VERSION "Mon"

NS_ :

BS_:

BU_: Mon ADAS Camera Gateway EPS APA Radar ESC radar
VAL_TABLE_ VitSig_LKA_main_switch 1 "LKA ON" 0 "LKA OFF" ;
VAL_TABLE_ VitSig_LC_Mode 3 "车道居中控制" 2 "车道保持辅助" 1 "车道偏离预警" 0 "预留" ;
VAL_TABLE_ VitSig_State_of_EPS_for_LKA 7 "Reserved" 6 "Reserved" 5 "Reserved" 4 "defect" 3 "active" 2 "available" 1 "authorized" 0 "unauthorized" ;
VAL_TABLE_ VitSig_Steering_wheel_sensor_dir 1 "Negative angles, decrease" 0 "Positive angles, increase" ;
VAL_TABLE_ VitSig_BCM_Status_Indicator 3 "Left and right indicator active" 2 "Left Indicator active" 1 "Right Indicator active" 0 "Indicator inactive" ;
VAL_TABLE_ VitSig_TCU_Gear_lever_position 15 "CMF disabled or unavailable" 14 "Reserved" 13 "Reserved" 12 "Reserved" 11 "Manual mode / Reserved1100" 10 "Reserved" 9 "Reserved" 8 "Reserved" 7 "Reserved" 6 "Reserved" 5 "Reserved" 4 "Reserved" 3 "D" 2 "N" 1 "R" 0 "P" ;
VAL_TABLE_ VLlaneType_valueTable 6 "road edge" 5 "bott's dotts" 4 "double lane mark" 3 "solid" 2 "dashed" 1 "undecided" 0 "invalid" ;
VAL_TABLE_ VLquality_valueTable 1 "high" 0 "low" ;
VAL_TABLE_ VitSig_General_state_of_LKA_3F2 7 "Reserved" 6 "Collision risk" 5 "Defect" 4 "Active" 3 "Autorized" 2 "Selected" 1 "Unselected" 0 "Unavailable" ;
VAL_TABLE_ VitSig_Deadman_dedicated_button 3 "Fault" 2 "Unconfigured" 1 "Request" 0 "No request" ;
VAL_TABLE_ VitSig_ASR_connection_dis_demand 1 "ASR disconnection requested" 0 "No ASR disconnection requested" ;
VAL_TABLE_ VitSig_Trailer_Present 1 "Trailer presence" 0 "Trailer absence" ;
VAL_TABLE_ VitSig_Permit_to_know_if_LKALPA 1 "LPA function" 0 "LKA function" ;
VAL_TABLE_ VitSig_TSR_Vision_Only_Sign_Type 255 "预留" 16 "预留" 15 "禁止驶入标志" 14 "停车让行标志" 13 "注意儿童标志" 12 "注意行人标志" 11 "注意危险标志" 10 "注意横风标志" 9 "注意信号灯标志" 8 "注意落石标志" 7 "易滑标志" 6 "下陡坡标志" 5 "上陡坡标志" 4 "十字交叉标志" 3 "施工标志" 2 "禁止右转标志" 1 "禁止左转标志" 0 "No TSR detected" ;
VAL_TABLE_ VitSig_ISA_Status 2 "ISA sign flash(over speed)" 1 "ISA system ON with limit value" 0 "ISA system OFF" ;
VAL_TABLE_ VitSig_ISA_Sign_Type 3 "End of speed limit sign" 2 "Speed limit sign with value" 1 "Speed limit sign without value" 0 "Default value" ;
VAL_TABLE_ VitSig_ISA_Value 31 "reserved" 30 "reserved" 29 "145km/h speed limit sign" 28 "135km/h speed limit sign" 27 "125km/h speed limit sign" 26 "115km/h speed limit sign" 25 "105km/h speed limit sign" 24 "95km/h speed limit sign" 23 "85km/h speed limit sign" 22 "75km/h speed limit sign" 21 "65km/h speed limit sign" 20 "55km/h speed limit sign" 19 "45km/h speed limit sign" 18 "35km/h speed limit sign" 17 "25km/h speed limit sign" 16 "15km/h speed limit sign" 15 "5km/h speed limit sign" 14 "140km/h speed limit sign" 13 "130km/h speed limit sign" 12 "120km/h speed limit sign" 11 "110km/h speed limit sign" 10 "100km/h speed limit sign" 9 "90km/h speed limit sign" 8 "80km/h speed limit sign" 7 "70km/h speed limit sign" 6 "60km/h speed limit sign" 5 "50km/h speed limit sign" 4 "40km/h speed limit sign" 3 "30km/h speed limit sign" 2 "20km/h speed limit sign" 1 "10km/h speed limit sign" 0 "No speed limit sign detected" ;
VAL_TABLE_ VitSig_ISA_Popup_text 3 "System fault" 2 "ISA system OFF (From ON to OFF)" 1 "ISA system ON (From OFF to ON)" 0 "No popup" ;
VAL_TABLE_ VitSig_ECU_operating_phase 15 "reserved" 14 "reserved" 13 "reserved" 12 "reserved" 11 "reserved" 10 "Service Alignment in processing" 9 "System fully operational" 8 "reserved" 7 "Camera Degraded" 6 "reserved" 5 "Camera Blocked/No image" 4 "reserved" 3 "Camera not calibrated" 2 "System Initializing/Warming Up" 1 "Status not available" 0 "system error" ;
VAL_TABLE_ VitSig_LKA_Switch_State 1 "LKA Switch ON" 0 "LKA Switch OFF" ;
VAL_TABLE_ VitSig_LKA_Mode_from_Camera 3 "LCA+LDW (resolved)" 2 "LKA+LDW" 1 "LDW only" 0 "OFF" ;
VAL_TABLE_ VitSig_hands_off_warning 1 "Hands off warning" 0 "No Hands off warning" ;
VAL_TABLE_ VitSig_LDW_Flag 3 "Invalid" 2 "Right LDW warining" 1 "Left LDW warining" 0 "No LDW warning" ;
VAL_TABLE_ VitSig_Vehicle_Lane_Display 15 "Invalid" 14 "Reserved" 13 "Reserved" 12 "Reserved" 11 "Reserved" 10 "Reserved" 9 "LKA intervention or LDW warning " 8 "LKA intervention or LDW warning " 7 "LKA intervention or LDW warning " 6 "LKA intervention or LDW warning " 5 "both lanes detected,both green" 4 "only right lane detected, green" 3 "only left detected,left green" 2 "available but no lane detected" 1 "ON but not in the working range " 0 "OFF and no lane line displayed" ;
VAL_TABLE_ VitSig_LKA_Status_Display 3 "Invalid" 2 "ON and system fault detected,red" 1 "ON and no system fault,  green" 0 "LKA + LDW OFF, no icon display" ;
VAL_TABLE_ VitSig_LDW_Status_Display 3 "Invalid" 2 "ON and system fault detected,red" 1 "ON and no system fault,green" 0 "LDW Only OFF, no icon display" ;
VAL_TABLE_ VitSig_LKA_action_indication 7 "Invalid" 6 "Reserved" 5 "Reserved" 4 "Reserved" 3 "available and with LKA,orange" 2 "available and without LKA, green" 1 "ON but not in working range" 0 "LKA+LDW OFF,no icon display" ;

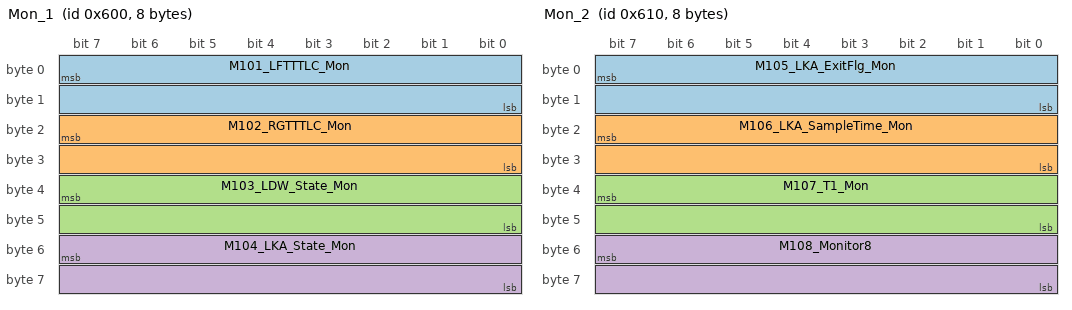
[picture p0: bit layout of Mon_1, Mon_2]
BO_ 1536 Mon_1: 8 Mon
 SG_ M101_LFTTTLC_Mon : 7|16@0- (0.01,0) [-327.68|327.67] "Mon" Vector__XXX
 SG_ M102_RGTTTLC_Mon : 23|16@0- (0.01,0) [-327.68|327.67] "Mon" Vector__XXX
 SG_ M103_LDW_State_Mon : 39|16@0- (0.01,0) [-327.68|327.67] "Mon" Vector__XXX
 SG_ M104_LKA_State_Mon : 55|16@0- (0.01,0) [-327.68|327.67] "Mon" Vector__XXX

BO_ 1552 Mon_2: 8 Mon
 SG_ M105_LKA_ExitFlg_Mon : 7|16@0- (0.01,0) [-327.68|327.67] "Mon" Vector__XXX
 SG_ M106_LKA_SampleTime_Mon : 23|16@0- (0.01,0) [-327.68|327.67] "Mon" Vector__XXX
 SG_ M107_T1_Mon : 39|16@0- (0.01,0) [-327.68|327.67] "Mon" Vector__XXX
 SG_ M108_Monitor8 : 55|16@0- (0.01,0) [-327.68|327.67] "Mon" Vector__XXX

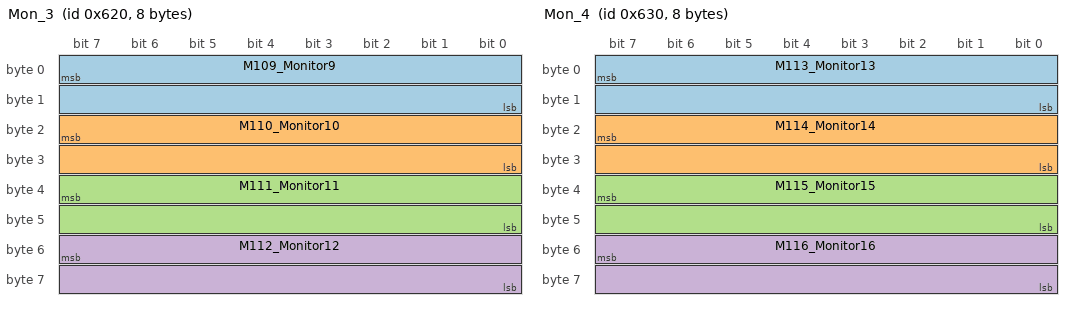
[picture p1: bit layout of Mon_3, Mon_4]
BO_ 1568 Mon_3: 8 Mon
 SG_ M109_Monitor9 : 7|16@0- (0.01,0) [-327.68|327.67] "Mon" Vector__XXX
 SG_ M110_Monitor10 : 23|16@0- (0.01,0) [-327.68|327.67] "Mon" Vector__XXX
 SG_ M111_Monitor11 : 39|16@0- (0.01,0) [-327.68|327.67] "Mon" Vector__XXX
 SG_ M112_Monitor12 : 55|16@0- (0.01,0) [-327.68|327.67] "Mon" Vector__XXX

BO_ 1584 Mon_4: 8 Mon
 SG_ M113_Monitor13 : 7|16@0- (0.01,0) [-327.68|327.67] "Mon" Vector__XXX
 SG_ M114_Monitor14 : 23|16@0- (0.01,0) [-327.68|327.67] "Mon" Vector__XXX
 SG_ M115_Monitor15 : 39|16@0- (0.01,0) [-327.68|327.67] "Mon" Vector__XXX
 SG_ M116_Monitor16 : 55|16@0- (0.01,0) [-327.68|327.67] "Mon" Vector__XXX

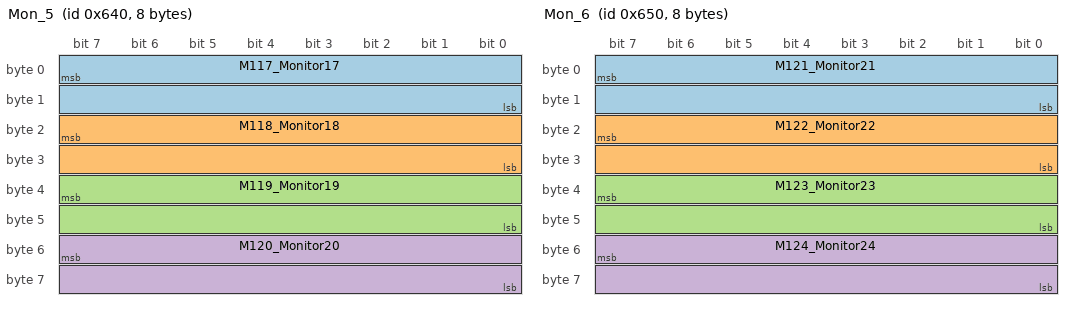
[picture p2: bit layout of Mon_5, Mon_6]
BO_ 1600 Mon_5: 8 Mon
 SG_ M117_Monitor17 : 7|16@0- (0.01,0) [-327.68|327.67] "Mon" Vector__XXX
 SG_ M118_Monitor18 : 23|16@0- (0.01,0) [-327.68|327.67] "Mon" Vector__XXX
 SG_ M119_Monitor19 : 39|16@0- (0.01,0) [-327.68|327.67] "Mon" Vector__XXX
 SG_ M120_Monitor20 : 55|16@0- (0.01,0) [-327.68|327.67] "Mon" Vector__XXX

BO_ 1616 Mon_6: 8 Mon
 SG_ M121_Monitor21 : 7|16@0- (0.01,0) [-327.68|327.67] "Mon" Vector__XXX
 SG_ M122_Monitor22 : 23|16@0- (0.01,0) [-327.68|327.67] "Mon" Vector__XXX
 SG_ M123_Monitor23 : 39|16@0- (0.01,0) [-327.68|327.67] "Mon" Vector__XXX
 SG_ M124_Monitor24 : 55|16@0- (0.01,0) [-327.68|327.67] "Mon" Vector__XXX

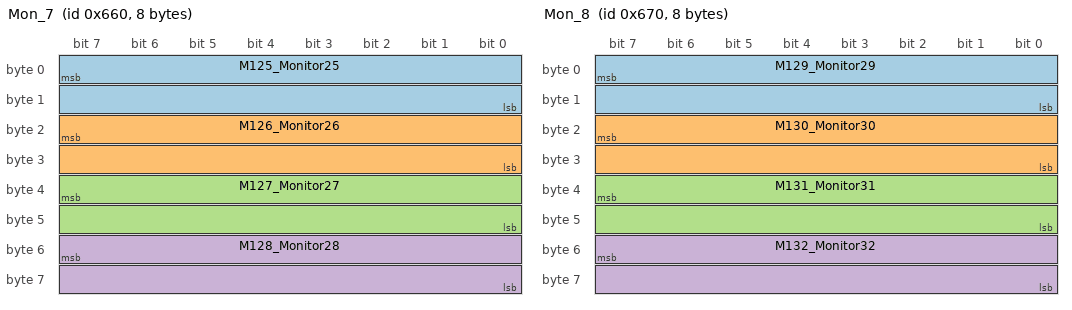
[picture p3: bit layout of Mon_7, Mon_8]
BO_ 1632 Mon_7: 8 Mon
 SG_ M125_Monitor25 : 7|16@0- (0.01,0) [-327.68|327.67] "Mon" Vector__XXX
 SG_ M126_Monitor26 : 23|16@0- (0.01,0) [-327.68|327.67] "Mon" Vector__XXX
 SG_ M127_Monitor27 : 39|16@0- (0.01,0) [-327.68|327.67] "Mon" Vector__XXX
 SG_ M128_Monitor28 : 55|16@0- (0.01,0) [-327.68|327.67] "Mon" Vector__XXX

BO_ 1648 Mon_8: 8 Mon
 SG_ M129_Monitor29 : 7|16@0- (0.01,0) [-327.68|327.67] "Mon" Vector__XXX
 SG_ M130_Monitor30 : 23|16@0- (0.01,0) [-327.68|327.67] "Mon" Vector__XXX
 SG_ M131_Monitor31 : 39|16@0- (0.01,0) [-327.68|327.67] "Mon" Vector__XXX
 SG_ M132_Monitor32 : 55|16@0- (0.01,0) [-327.68|327.67] "Mon" Vector__XXX

BO_ 1359 GW_550_PSA1: 8 Gateway
 SG_ LKA_main_switch : 5|1@0+ (1,0) [0|1] ""  ADAS,Camera
 SG_ LC_Mode : 7|2@0+ (1,0) [0|3] ""  ADAS,Camera

BO_ 1172 EPS_495_PSA1: 4 EPS
 SG_ State_of_EPS_for_LKA_function : 20|3@0+ (1,0) [0|7] ""  ADAS,Camera
 SG_ Steering_wheel_torque : 7|8@0- (0.25,0) [-32|31.5] "N.m"  ADAS,Camera

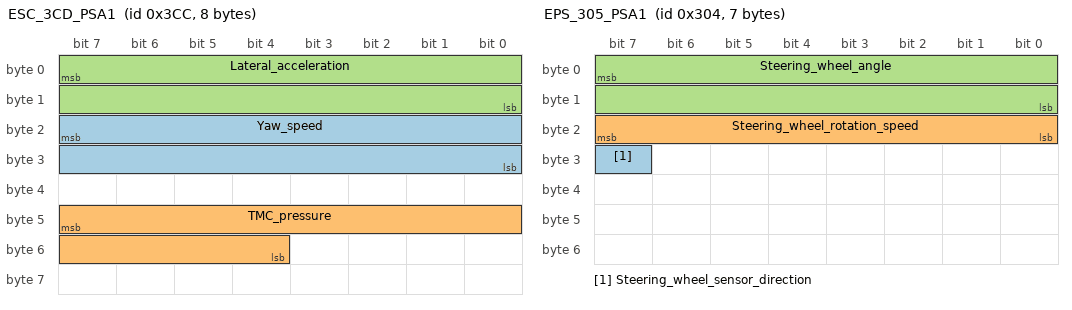
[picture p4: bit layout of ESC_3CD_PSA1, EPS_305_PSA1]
BO_ 972 ESC_3CD_PSA1: 8 ESC
 SG_ Yaw_speed : 23|16@0- (0.1,0) [-100|100] "Degree/s"  EPS,Gateway,APA,Camera,ADAS
 SG_ TMC_pressure : 47|12@0+ (0.1,-55) [-55|354.4] "Bar"  Gateway,APA,Radar,Camera,ADAS
 SG_ Lateral_acceleration : 7|16@0- (0.05,0) [-15|15] "m/s2"  EPS,Gateway,APA,Radar,Camera,ADAS

BO_ 908 ESC_38D_PSA1: 8 ESC
 SG_ Vehicle_speed_of_wheelsensor : 7|16@0+ (0.01,0) [0|655.34] "km/h"  EPS,Gateway,APA,Radar,Camera,ADAS

BO_ 812 GW_32D_PSA1: 8 Gateway
 SG_ ACCEL_LONGI_CALIB : 7|12@0+ (0.02,-40.96) [-40.96|40.92] "m/s2"  Radar,Camera,ADAS

BO_ 772 EPS_305_PSA1: 7 EPS
 SG_ Steering_wheel_sensor_direction : 31|1@0+ (1,0) [0|0] ""  ADAS,Camera,ESC,Gateway,Radar
 SG_ Steering_wheel_rotation_speed : 23|8@0+ (4,0) [0|1016] "Degree/s"  ADAS,APA,Camera,ESC,Gateway,Radar
 SG_ Steering_wheel_angle : 7|16@0- (0.1,0) [-780|780] "Degree"  ADAS,APA,Camera,ESC,Gateway,Radar

BO_ 1105 GW_452_PSA1: 6 Gateway
 SG_ BCM_Status_Indicator : 5|2@0+ (1,0) [0|0] ""  APA,Radar,Camera,ADAS

BO_ 840 GW_349_PSA1: 8 Gateway
 SG_ TCU_Gear_lever_position : 27|4@0+ (1,0) [0|0] ""  ESC,APA,Radar,Camera,ADAS

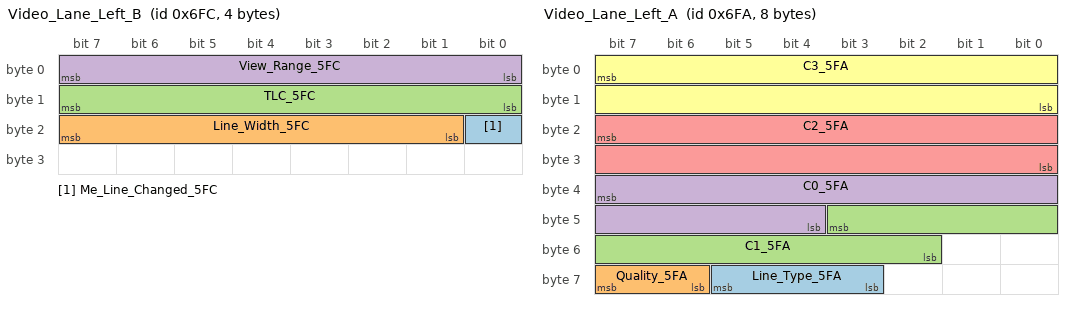
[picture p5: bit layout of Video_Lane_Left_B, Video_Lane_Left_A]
BO_ 1788 Video_Lane_Left_B: 4 Camera
 SG_ Me_Line_Changed_5FC : 16|1@0+ (1,0) [0|1] ""  radar,ADAS
 SG_ Line_Width_5FC : 23|7@0+ (0.01,0) [0|1.27] "m"  radar,ADAS
 SG_ TLC_5FC : 15|8@0+ (0.01,0) [0|2.55] "s"  radar,ADAS
 SG_ View_Range_5FC : 7|8@0+ (0.5,0) [0|127.5] "m"  radar,ADAS

BO_ 1786 Video_Lane_Left_A: 8 Camera
 SG_ Line_Type_5FA : 61|3@0+ (1,0) [0|7] ""  radar,ADAS
 SG_ Quality_5FA : 63|2@0+ (1,0) [0|3] ""  radar,ADAS
 SG_ C1_5FA : 43|10@0- (0.0009765625,0) [-0.357|0.357] ""  radar,ADAS
 SG_ C0_5FA : 39|12@0- (0.01,0) [-20.48|20.47] "m"  radar,ADAS
 SG_ C2_5FA : 23|16@0- (1E-006,0) [-0.032768|0.032766] "m-1"  radar,ADAS
 SG_ C3_5FA : 7|16@0- (4E-009,0) [-0.000131072|0.000131068] "m-2"  radar,ADAS

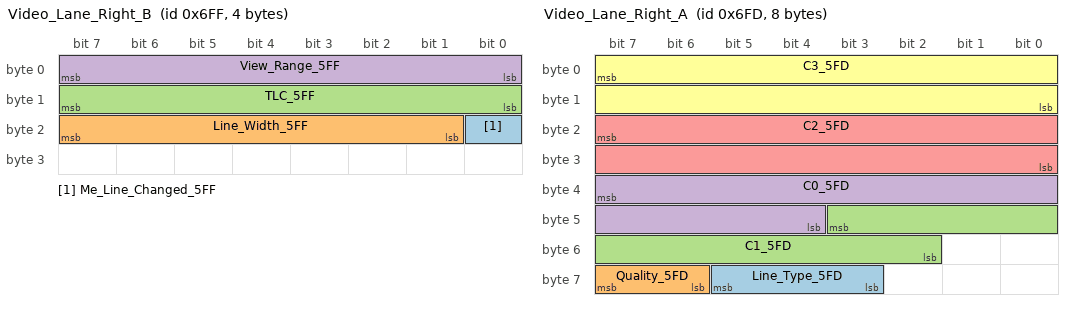
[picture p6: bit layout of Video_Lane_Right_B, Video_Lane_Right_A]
BO_ 1791 Video_Lane_Right_B: 4 Camera
 SG_ Me_Line_Changed_5FF : 16|1@0+ (1,0) [0|1] ""  radar,ADAS
 SG_ Line_Width_5FF : 23|7@0+ (0.01,0) [0|1.27] "m"  radar,ADAS
 SG_ TLC_5FF : 15|8@0+ (0.01,0) [0|2.55] "s"  radar,ADAS
 SG_ View_Range_5FF : 7|8@0+ (0.5,0) [0|127.5] "m"  radar,ADAS

BO_ 1789 Video_Lane_Right_A: 8 Camera
 SG_ Line_Type_5FD : 61|3@0+ (1,0) [0|7] ""  radar,ADAS
 SG_ Quality_5FD : 63|2@0+ (1,0) [0|3] ""  radar,ADAS
 SG_ C1_5FD : 43|10@0- (0.0009765625,0) [-0.357|0.357] ""  radar,ADAS
 SG_ C0_5FD : 39|12@0- (0.01,0) [-20.48|20.47] "m"  radar,ADAS
 SG_ C2_5FD : 23|16@0- (1E-006,0) [-0.032768|0.032766] "m-1"  radar,ADAS
 SG_ C3_5FD : 7|16@0- (4E-009,0) [-0.000131072|0.000131068] "m-2"  radar,ADAS

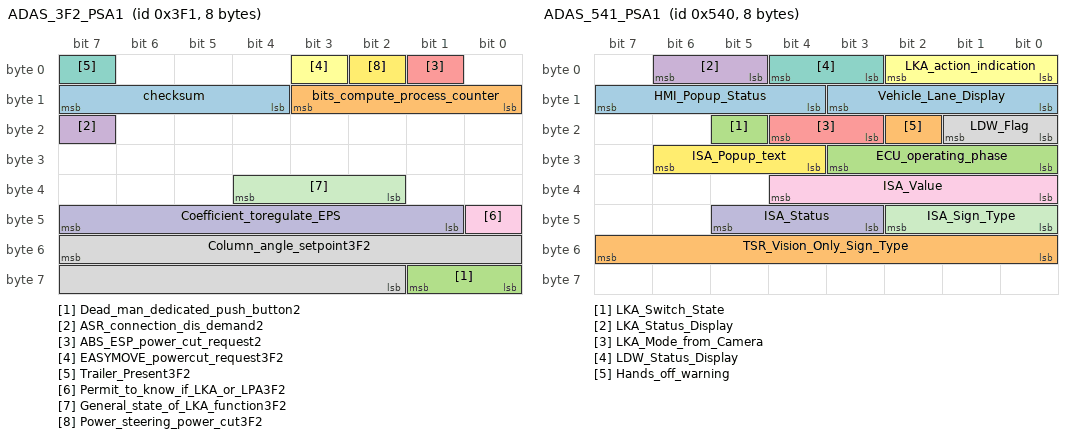
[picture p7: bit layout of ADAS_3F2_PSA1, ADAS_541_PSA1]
BO_ 1009 ADAS_3F2_PSA1: 8 ADAS
 SG_ checksum : 15|4@0+ (1,0) [0|15] "" Vector__XXX
 SG_ bits_compute_process_counter : 11|4@0+ (1,0) [0|0] "" Vector__XXX
 SG_ Dead_man_dedicated_push_button2 : 57|2@0+ (1,0) [0|0] ""  APA,ESC
 SG_ ASR_connection_dis_demand2 : 23|1@0+ (1,0) [0|0] ""  ESC
 SG_ ABS_ESP_power_cut_request2 : 1|1@0+ (1,0) [0|0] ""  ESC
 SG_ EASYMOVE_powercut_request3F2 : 3|1@0+ (1,0) [0|0] ""  ESC
 SG_ Trailer_Present3F2 : 7|1@0+ (1,0) [0|0] ""  ESC
 SG_ Column_angle_setpoint3F2 : 55|14@0- (0.1,0) [-780|780] "Degree"  EPS
 SG_ Permit_to_know_if_LKA_or_LPA3F2 : 40|1@0+ (1,0) [0|0] ""  EPS
 SG_ Coefficient_toregulate_EPS : 47|7@0+ (0.01,0) [0|1] ""  EPS
 SG_ General_state_of_LKA_function3F2 : 36|3@0+ (1,0) [0|0] ""  EPS
 SG_ Power_steering_power_cut3F2 : 2|1@0+ (1,0) [0|0] ""  EPS

BO_ 1344 ADAS_541_PSA1: 8 ADAS
 SG_ Vehicle_Lane_Display : 11|4@0+ (1,0) [0|0] ""  Gateway
 SG_ TSR_Vision_Only_Sign_Type : 55|8@0+ (1,0) [0|0] ""  Gateway
 SG_ LKA_Switch_State : 21|1@0+ (1,0) [0|0] ""  Gateway
 SG_ LKA_Status_Display : 6|2@0+ (1,0) [0|0] ""  Gateway
 SG_ LKA_Mode_from_Camera : 20|2@0+ (1,0) [0|0] ""  Gateway
 SG_ LKA_action_indication : 2|3@0+ (1,0) [0|0] ""  Gateway
 SG_ LDW_Status_Display : 4|2@0+ (1,0) [0|0] ""  Gateway
 SG_ LDW_Flag : 17|2@0+ (1,0) [0|0] ""  Gateway
 SG_ ISA_Value : 36|5@0- (1,0) [0|31] "km/h"  Gateway
 SG_ ISA_Status : 45|3@0+ (1,0) [0|0] ""  Gateway
 SG_ ISA_Sign_Type : 42|3@0+ (1,0) [0|0] ""  Gateway
 SG_ ISA_Popup_text : 30|3@0+ (1,0) [0|0] ""  Gateway
 SG_ HMI_Popup_Status : 15|4@0+ (1,0) [0|0] ""  Gateway
 SG_ Hands_off_warning : 18|1@0+ (1,0) [0|0] ""  Gateway
 SG_ ECU_operating_phase : 27|4@0+ (1,0) [0|0] ""  Gateway

CM_ SG_ 1359 LKA_main_switch "LKA开启开关";
CM_ SG_ 1359 LC_Mode "LKA功能选择";
CM_ SG_ 1172 State_of_EPS_for_LKA_function "LKA功能的EPS状态";
CM_ SG_ 1172 Steering_wheel_torque "方向盘转矩";
CM_ SG_ 972 Yaw_speed "横摆角速度";
CM_ SG_ 972 TMC_pressure "主缸压力";
CM_ SG_ 972 Lateral_acceleration "侧向加速度";
CM_ SG_ 908 Vehicle_speed_of_wheelsensor "车速（轮速传感器)";
CM_ SG_ 812 ACCEL_LONGI_CALIB "标定后的当前纵向加速度";
CM_ SG_ 772 Steering_wheel_sensor_direction "转向传感器方向";
CM_ SG_ 772 Steering_wheel_rotation_speed "转向旋转速度";
CM_ SG_ 772 Steering_wheel_angle "转向角信号";
CM_ SG_ 1105 BCM_Status_Indicator "转向灯状态（包括双闪）";
CM_ SG_ 840 TCU_Gear_lever_position "换挡手柄位置";
CM_ SG_ 1788 Me_Line_Changed_5FC "is one for one cycle when lane model switched.";
CM_ SG_ 1786 C1_5FA "57 degrees, 0.06 degrees resolution";
CM_ SG_ 1786 C2_5FA "250m minimal radius";
CM_ SG_ 1791 Me_Line_Changed_5FF "is one for one cycle when lane model switched.";
CM_ SG_ 1789 C1_5FD "57 degrees, 0.06 degrees resolution";
CM_ SG_ 1789 C2_5FD "250m minimal radius";
CM_ SG_ 1009 Dead_man_dedicated_push_button2 "自动泊车功能开关";
CM_ SG_ 1009 ASR_connection_dis_demand2 "ASR连接/不连接命令（ESC OFF开关指令）";
CM_ SG_ 1009 ABS_ESP_power_cut_request2 "ABS ESP供电切断请求";
CM_ SG_ 1009 EASYMOVE_powercut_request3F2 "EASYMOVE供电切断请求";
CM_ SG_ 1009 Trailer_Present3F2 "拖车稳定系统使用状态";
CM_ SG_ 1009 Column_angle_setpoint3F2 "计算角度";
CM_ SG_ 1009 Permit_to_know_if_LKA_or_LPA3F2 "LKA或LPA功能允许";
CM_ SG_ 1009 Coefficient_toregulate_EPS "EPS应用扭矩系数";
CM_ SG_ 1009 Power_steering_power_cut3F2 "动力转向切断请求";
CM_ SG_ 1344 Vehicle_Lane_Display "车道线显示";
CM_ SG_ 1344 TSR_Vision_Only_Sign_Type "标识符的种类";
CM_ SG_ 1344 LKA_Switch_State "LKA功能开启";
CM_ SG_ 1344 LKA_Status_Display "LKA状态指示";
CM_ SG_ 1344 LKA_Mode_from_Camera "摄像头发出的LKA 功能模式";
CM_ SG_ 1344 LKA_action_indication "LKA动作指示";
CM_ SG_ 1344 LDW_Status_Display "LDW Only 状态指示";
CM_ SG_ 1344 LDW_Flag "LDW 报警状态";
CM_ SG_ 1344 ISA_Value "ISA功能的速度值";
CM_ SG_ 1344 ISA_Status "ISA功能报警状态";
CM_ SG_ 1344 ISA_Sign_Type "ISA限速标识类型";
CM_ SG_ 1344 ISA_Popup_text "ISA功能文字显示";
CM_ SG_ 1344 HMI_Popup_Status "仪表弹出文字 表示状态变化";
CM_ SG_ 1344 Hands_off_warning "脱手报警";
CM_ SG_ 1344 ECU_operating_phase "当前摄像头工作状态";
BA_DEF_  "BusType" STRING ;
BA_DEF_DEF_  "BusType" "CAN";
VAL_ 1359 LKA_main_switch 1 "LKA ON" 0 "LKA OFF" ;
VAL_ 1359 LC_Mode 3 "车道居中控制" 2 "车道保持辅助" 1 "车道偏离预警" 0 "预留" ;
VAL_ 1172 State_of_EPS_for_LKA_function 7 "Reserved" 6 "Reserved" 5 "Reserved" 4 "defect" 3 "active" 2 "available" 1 "authorized" 0 "unauthorized" ;
VAL_ 772 Steering_wheel_sensor_direction 1 "Negative angles, decrease" 0 "Positive angles, increase" ;
VAL_ 1105 BCM_Status_Indicator 3 "Left and right indicator active" 2 "Left Indicator active" 1 "Right Indicator active" 0 "Indicator inactive" ;
VAL_ 1786 Line_Type_5FA 5 "bott's dotts" 4 "double lane mark" 3 "dashed" 2 "road edge" 1 "solid" 0 "undecided" ;
VAL_ 1786 Quality_5FA 3 "High" 2 "Medium_PredictedOrLowScore" 1 "Low2_InsufficientScore" 0 "Low1_NoLineDetected" ;
VAL_ 1009 Dead_man_dedicated_push_button2 3 "Fault" 2 "Unconfigured" 1 "Request" 0 "No request" ;
VAL_ 1009 ASR_connection_dis_demand2 1 "ASR disconnection requested" 0 "No ASR disconnection requested" ;
VAL_ 1009 ABS_ESP_power_cut_request2 1 "Power cut request" 0 "Not request" ;
VAL_ 1009 EASYMOVE_powercut_request3F2 1 "Power cut request" 0 "Not request" ;
VAL_ 1009 Trailer_Present3F2 1 "Trailer presence" 0 "Trailer absence" ;
VAL_ 1009 Permit_to_know_if_LKA_or_LPA3F2 1 "LPA function" 0 "LKA function" ;
VAL_ 1009 General_state_of_LKA_function3F2 7 "Reserved" 6 "Collision risk" 5 "Defect" 4 "Active" 3 "Autorized" 2 "Selected" 1 "Unselected" 0 "Unavailable" ;
VAL_ 1009 Power_steering_power_cut3F2 1 "Power cut request" 0 "Not request" ;
VAL_ 1344 Vehicle_Lane_Display 15 "Invalid" 14 "Reserved" 13 "Reserved" 12 "Reserved" 11 "Reserved" 10 "Reserved" 9 "LKA intervention or LDW warning " 8 "LKA intervention or LDW warning " 7 "LKA intervention or LDW warning " 6 "LKA intervention or LDW warning " 5 "both lanes detected,both green" 4 "only right lane detected, green" 3 "only left detected,left green" 2 "available but no lane detected" 1 "ON but not in the working range " 0 "OFF and no lane line displayed" ;
VAL_ 1344 TSR_Vision_Only_Sign_Type 255 "预留" 16 "预留" 15 "禁止右转标志" 14 "禁止左转标志" 13 "禁止驶入标志" 12 "停车让行标志" 11 "注意儿童标志" 10 "注意行人标志" 9 "注意危险标志" 8 "注意横风标志" 7 "注意信号灯标志" 6 "注意落石标志" 5 "易滑标志" 4 "下陡坡标志" 3 "上陡坡标志" 2 "十字交叉标志" 1 "施工标志" 0 "No TSR detected" ;
VAL_ 1344 LKA_Switch_State 1 "LKA Switch ON" 0 "LKA Switch OFF" ;
VAL_ 1344 LKA_Status_Display 3 "Invalid" 2 "ON and system fault detected,red" 1 "ON and no system fault,  green" 0 "LKA + LDW OFF, no icon display" ;
VAL_ 1344 LKA_Mode_from_Camera 3 "LCA+LDW (resolved)" 2 "LKA+LDW" 1 "LDW only" 0 "OFF" ;
VAL_ 1344 LKA_action_indication 7 "Invalid" 6 "Reserved" 5 "Reserved" 4 "Reserved" 3 "available and with LKA,orange" 2 "available and without LKA, green" 1 "ON but not in working range" 0 "LKA+LDW OFF,no icon display" ;
VAL_ 1344 LDW_Status_Display 3 "Invalid" 2 "ON and system fault detected,red" 1 "ON and no system fault,green" 0 "LDW Only OFF, no icon display" ;
VAL_ 1344 LDW_Flag 3 "Invalid" 2 "Right LDW warining" 1 "Left LDW warining" 0 "No LDW warning" ;
VAL_ 1344 ISA_Value 31 "reserved" 30 "reserved" 29 "145km/h speed limit sign" 28 "135km/h speed limit sign" 27 "125km/h speed limit sign" 26 "115km/h speed limit sign" 25 "105km/h speed limit sign" 24 "95km/h speed limit sign" 23 "85km/h speed limit sign" 22 "75km/h speed limit sign" 21 "65km/h speed limit sign" 20 "55km/h speed limit sign" 19 "45km/h speed limit sign" 18 "35km/h speed limit sign" 17 "25km/h speed limit sign" 16 "15km/h speed limit sign" 15 "5km/h speed limit sign" 14 "140km/h speed limit sign" 13 "130km/h speed limit sign" 12 "120km/h speed limit sign" 11 "110km/h speed limit sign" 10 "100km/h speed limit sign" 9 "90km/h speed limit sign" 8 "80km/h speed limit sign" 7 "70km/h speed limit sign" 6 "60km/h speed limit sign" 5 "50km/h speed limit sign" 4 "40km/h speed limit sign" 3 "30km/h speed limit sign" 2 "20km/h speed limit sign" 1 "10km/h speed limit sign" 0 "No speed limit sign detected" ;
VAL_ 1344 ISA_Status 7 "Reserved" 6 "Reserved" 5 "Reserved" 4 "Reserved" 3 "System fault" 2 "ISA sign flash(over speed)" 1 "ISA system ON with limit value" 0 "ISA system OFF" ;
VAL_ 1344 ISA_Sign_Type 7 "Reserved" 6 "Reserved" 5 "Reserved" 4 "Reserved" 3 "End of speed limit sign" 2 "Speed limit sign with value" 1 "Speed limit sign without value" 0 "Default value" ;
VAL_ 1344 ISA_Popup_text 7 "Reserved" 6 "Reserved" 5 "Reserved" 4 "Reserved" 3 "System fault" 2 "ISA system OFF (From ON to OFF)" 1 "ISA system ON (From OFF to ON)" 0 "No popup" ;
VAL_ 1344 HMI_Popup_Status 15 "Invalid" 14 "Reserved" 13 "Reserved" 12 "Reserved" 11 "Reserved" 10 "Reserved" 9 "Reserved" 8 "LaneSense Off" 7 "LaneSense Canbe Switched On" 6 "LaneSenseDisable - System Fault" 5 "LaneSense Available" 4 "Front Camera Blocked" 3 "LaneSenseTemporarily Unavailable" 2 "PleaseHands on Steering Wheel" 1 "3 second popup=LaneSense On" 0 "Default value" ;
VAL_ 1344 Hands_off_warning 1 "Hands off warning" 0 "No Hands off warning" ;
VAL_ 1344 ECU_operating_phase 15 "reserved" 14 "reserved" 13 "reserved" 12 "reserved" 11 "reserved" 10 "Service Alignment in processing" 9 "System fully operational" 8 "reserved" 7 "Camera Degraded" 6 "reserved" 5 "Camera Blocked/No image" 4 "reserved" 3 "Camera not calibrated" 2 "System Initializing/Warming Up" 1 "Status not available" 0 "system error" ;
